# GAP8 register map
Vendor: GreenWaves Technologies SAS; Series: GAP8; File version: 1.3.1
CPU: other r1p0, little endian, MPU, no FPU, I-cache, DTCM, false interrupt priority bits
Registers are 32-bit, read-write, reset 0x0 unless marked. A register's access mark holds for its fields unless they carry their own. Offsets are from the block's base; [hi:lo] are bit positions; 'fields as' and 'values as' point back to an identical list.

## hyper — uDMA Hyperbus interface
Base 0x1A102180
0x00 rx_saddr — uDMA RX HYPERBUS buffer base address configuration register.
  [15:0] rx_saddr — RX buffer base address bitfield: - Read: returns value of the buffer pointer until transfer is finished. Else returns 0. - Write: sets RX buffer base address
0x04 rx_size — uDMA RX HYPERBUS buffer size configuration register.
  [16:0] rx_size — RX buffer size bitfield in bytes. (128kBytes maximum) - Read: returns remaining buffer size to transfer. - Write: sets buffer size.
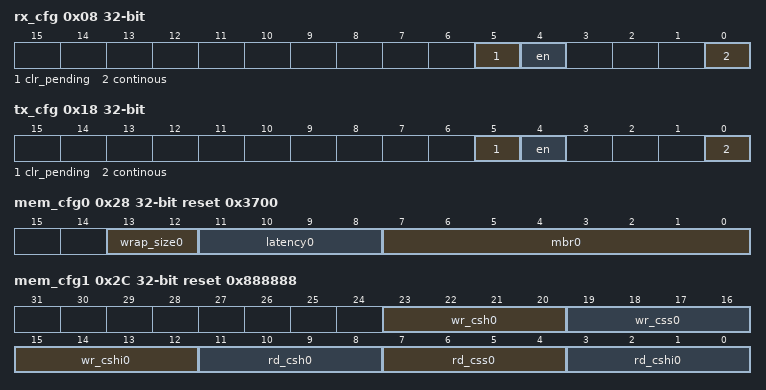
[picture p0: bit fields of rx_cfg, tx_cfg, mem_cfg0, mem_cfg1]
0x08 rx_cfg — uDMA RX HYPERBUS stream configuration register.
  [5] clr_pending — RX channel clear and stop transfer RX transfer pending in queue status flag
    on write: 0=disable (feature is disabled); 1=stop and clear the on-going transfer | on read: 0=no pending transfer in the queue; 1=pending transfer in the queue
  [4] en — RX channel enable and start transfer bitfield This signal is used also to queue a transfer if one is already ongoing.
    0=disable (feature is disabled); 1=start (enable and start the transfer)
  [0] continous — RX channel continuous mode bitfield At the end of the buffer transfer, the uDMA reloads the address / buffer size and starts a new transfer.
    0=disabled (feature is disabled); 1=enabled (feature is enabled)
0x10 tx_saddr — uDMA TX HYPERBUS buffer base address configuration register.
  [15:0] tx_saddr — TX buffer base address bitfield: - Read: returns value of the buffer pointer until transfer is finished. Else returns 0. - Write: sets buffer base address
0x14 tx_size — uDMA TX HYPERBUS buffer size configuration register.
  [16:0] tx_size — TX buffer size bitfield in bytes. (128kBytes maximum) - Read: returns remaining buffer size to transfer. - Write: sets buffer size.
0x18 tx_cfg — uDMA TX HYPERBUS stream configuration register.
  [5] clr_pending — TX channel clear and stop transfer bitfield TX transfer pending in queue status flag
    on write: 0=disabled (feature is disabled); 1=stop and clear the on-going transfer | on read: 0=no pending transfer in the queue; 1=pending transfer in the queue
  [4] en — TX channel enable and start transfer bitfield This signal is used also to queue a transfer if one is already ongoing.
    0=disabled (feature is disabled); 1=start (enable and start the transfer)
  [0] continous — TX channel continuous mode bitfield At the end of the buffer transfer, the uDMA reloads the address / buffer size and starts a new transfer.
    values as rx_cfg.continous
0x20 ext_addr — Memory access address register.
  [31:0] saddr — Memory access address bitfield.
0x28 mem_cfg0 reset 0x3700 — Memory Control Configuration 0 register.
  [13:12] wrap_size0 — Wrapped Burst Size bitfield
    0=not_used (set to not used); 1=64_bytes (set to 64 bytes); 2=16_bytes (set to 16 bytes); 3=32_bytes (set to 32 bytes)
  [11:8] latency0 — Latency Cycle value for HyperRAM bitfield. When using HyperRAM memory, this bit should be set to the same value as the read latency in configuration register of HyperRAM memory the read latency in configuration register of HyperRAM memory. - Others: 6 CK
    0=5_ck (set to 5 CK); 1=6_ck (set to 6 CK); 14=3_ck (set to 3 CK); 15=4_ck (set to 4 CK)
  [7:0] mbr0 — Memory Base Address 0 for RAM bitfield. The base address of addressable region to each memory is set up. Since register can be set in 16M bytes boundary, lower 24 bit is fixed to 0.
0x2C mem_cfg1 reset 0x888888 — Memory Control Configuration 1 register.
  [23:20] wr_csh0 — Write Chip Select Hold After CK Falling Edge bitfield = 1 CK * (1 + val)
  [19:16] wr_css0 — Write Chip Select Setup to next CK Rising Edge bitfield = 1 CK * (1 + val)
  [15:12] wr_cshi0 — Write Chip Select High Between Operations bitfield = 1.5 CK * (1 + val)
  [11:8] rd_csh0 — Read Chip Select Hold After CK Falling Edge bitfield = 1 CK * (1 + val)
  [7:4] rd_css0 — Read Chip Select Setup to next CK Rising Edge bitfield = 1 CK * (1 + val)
  [3:0] rd_cshi0 — Read Chip Select High Between Operations bitfield = 1.5 CK * (1 + val)
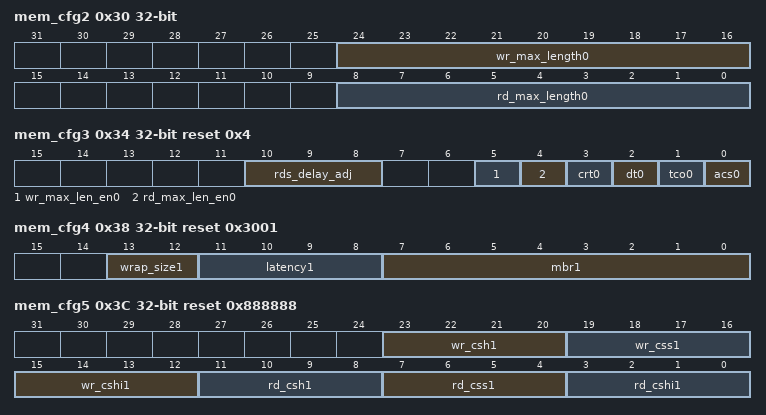
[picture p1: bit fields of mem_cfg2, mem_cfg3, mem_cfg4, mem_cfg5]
0x30 mem_cfg2 — Memory Control Configuration 2 register.
  [24:16] wr_max_length0 — Write Maximum Length bitfield = 2 CK * (1 + val)
  [8:0] rd_max_length0 — Read Maximum Length bitfield (Maximum access data length in order to restrict HyperBus CS# assertion time) = 2 CK * (1 + val)
0x34 mem_cfg3 reset 0x4 — Memory Control Configuration 3 register.
  [10:8] rds_delay_adj — RDS Delay Configuration bitfield
  [5] wr_max_len_en0 — Write Maximum Length Enable bitfield (enables maximum access data length control for restricting HyperBus CS# assertion time by MAXLEN bit)
    0=Disable maximum access data length control; 1=Enable maximum access data length control
  [4] rd_max_len_en0 — Read Maximum Length Enable bitfield (enables maximum access data length control for restricting HyperBus CS# assertion time by MAXLEN bit)
    values as wr_max_len_en0
  [3] crt0 — Configuration Register Target bitfield (indicates whether access is to memory space or register space) -This bit is mapped to CA[46] bit in command/address cycle to HyperRAM device. -When using HyperFlash memory, this bit should be set to 0.
    0=Memory space; 1=Configuration register space
  [2] dt0 — Device Type bitfield (set as a device type of connected memory)
    0=hyperflash (set to HyperFlash); 1=hyperram (set to HyperRAM)
  [1] tco0 — True Continuous Merging Option bitfield (set when the wrap transaction and subsequent continuous transaction can be merged)
    0=no_merge (No merging WRAP and INCR.); 1=merge (Merging WRAP and INCR.)
  [0] acs0 — Asymmetry Cache System Support bitfield (set when the different wrap size (cache size) is required by multi-core in system)
    values as tco0
0x38 mem_cfg4 reset 0x3001 — Memory Control Configuration 4 register.
  [13:12] wrap_size1 — Wrapped Burst Size bitfield
    values as mem_cfg0.wrap_size0
  [11:8] latency1 — This bit is ignored when the DEVTYPE in HYPERBUS_CTRL_MCRi register is chosen to the HyperFlash memory (Defult latency is 1 for write, 5 for read).
  [7:0] mbr1 — Memory Base Address1 for FLASH bitfield. HYPERBUS_MBRi+1 register for CSi+1# must be set higher than HYPERBUS_MBRi register for CSi#
0x3C mem_cfg5 reset 0x888888 — Memory Control Configuration 5 register.
  [23:20] wr_csh1 — Write Chip Select Hold After CK Falling Edge bitfield = 1 CK * (1 + val)
  [19:16] wr_css1 — Write Chip Select Setup to next CK Rising Edge bitfield = 1 CK * (1 + val)
  [15:12] wr_cshi1 — Write Chip Select High Between Operations bitfield = 1.5 CK * (1 + val)
  [11:8] rd_csh1 — Read Chip Select Hold After CK Falling Edge bitfield = 1 CK * (1 + val)
  [7:4] rd_css1 — Read Chip Select Setup to next CK Rising Edge bitfield = 1 CK * (1 + val)
  [3:0] rd_cshi1 — Read Chip Select High Between Operations bitfield = 1.5 CK * (1 + val)
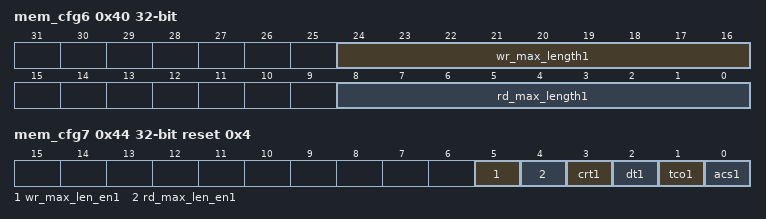
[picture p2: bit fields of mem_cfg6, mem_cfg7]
0x40 mem_cfg6 — Memory Control Configuration 6 register.
  [24:16] wr_max_length1 — Write Maximum Length bitfield = 2 CK * (1 + val)
  [8:0] rd_max_length1 — Read Maximum Length bitfield (Maximum access data length in order to restrict HyperBus CS# assertion time) = 2 CK * (1 + val)
0x44 mem_cfg7 reset 0x4 — Memory Control Configuration 7 register.
  [5] wr_max_len_en1 — Write Maximum Length Enable bitfield (enables maximum access data length control for restricting HyperBus CS# assertion time by MAXLEN bit)
    values as mem_cfg3.wr_max_len_en0
  [4] rd_max_len_en1 — Read Maximum Length Enable bitfield (enables maximum access data length control for restricting HyperBus CS# assertion time by MAXLEN bit)
    values as mem_cfg3.wr_max_len_en0
  [3] crt1 — Configuration Register Target bitfield (indicates whether access is to memory space or register space) This bit is mapped to CA[46] bit in command/address cycle to HyperRAM device. When using HyperFlash memory, this bit should be set to 0.
    0=Memory space; 1=Configuration register space
  [2] dt1 — Device Type bitfield (set as a device type of connected memory)
    values as mem_cfg3.dt0
  [1] tco1 — True Continuous Merging Option bitfield (set when the wrap transaction and subsequent continuous transaction can be merged)
    values as mem_cfg3.tco0
  [0] acs1 — Asymmetry Cache System Support bitfield (set when the different wrap size (cache size) is required by multi-core in system)
    values as mem_cfg3.tco0
